AUTOSAR XML (schema 4-3-0)
package /Can_Comm_Diag
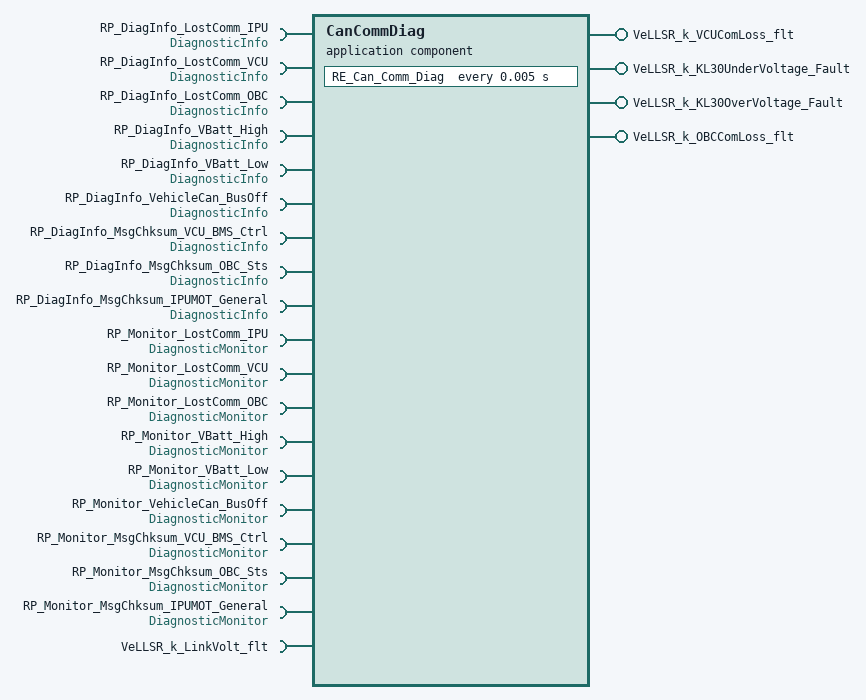
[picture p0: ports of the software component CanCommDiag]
  application sw component type CanCommDiag
    18 x require port:
      RP_DiagInfo_LostComm_IPU: required-interface=DiagnosticInfo
      RP_DiagInfo_LostComm_VCU: required-interface=DiagnosticInfo
      RP_DiagInfo_LostComm_OBC: required-interface=DiagnosticInfo
      RP_DiagInfo_VBatt_High: required-interface=DiagnosticInfo
      RP_DiagInfo_VBatt_Low: required-interface=DiagnosticInfo
      RP_DiagInfo_VehicleCan_BusOff: required-interface=DiagnosticInfo
      RP_DiagInfo_MsgChksum_VCU_BMS_Ctrl: required-interface=DiagnosticInfo
      RP_DiagInfo_MsgChksum_OBC_Sts: required-interface=DiagnosticInfo
      RP_DiagInfo_MsgChksum_IPUMOT_General: required-interface=DiagnosticInfo
      RP_Monitor_LostComm_IPU: required-interface=DiagnosticMonitor
      RP_Monitor_LostComm_VCU: required-interface=DiagnosticMonitor
      RP_Monitor_LostComm_OBC: required-interface=DiagnosticMonitor
      RP_Monitor_VBatt_High: required-interface=DiagnosticMonitor
      RP_Monitor_VBatt_Low: required-interface=DiagnosticMonitor
      RP_Monitor_VehicleCan_BusOff: required-interface=DiagnosticMonitor
      RP_Monitor_MsgChksum_VCU_BMS_Ctrl: required-interface=DiagnosticMonitor
      RP_Monitor_MsgChksum_OBC_Sts: required-interface=DiagnosticMonitor
      RP_Monitor_MsgChksum_IPUMOT_General: required-interface=DiagnosticMonitor
    provide port VeLLSR_k_VCUComLoss_flt: provided-interface=VeLLSR_k_VCUComLoss_flt
    require port VeLLSR_k_LinkVolt_flt: required-interface=VeLLSR_k_LinkVolt_flt
    provide port VeLLSR_k_KL30UnderVoltage_Fault: provided-interface=VeLLSR_k_KL30UnderVoltage_Fault
    provide port VeLLSR_k_KL30OverVoltage_Fault: provided-interface=VeLLSR_k_KL30OverVoltage_Fault
    provide port VeLLSR_k_OBCComLoss_flt: provided-interface=VeLLSR_k_OBCComLoss_flt
    behavior SwcInternalBehavior_0: data-type-mapping=[DHSR_CodeDataTypeMappingsSet, HVSR_CodeDataTypeMappingsSet]
      timing event TimingEvent_0: start-on-event=RE_Can_Comm_Diag, period=0.005
      runnable RE_Can_Comm_Diag: symbol=Perform_Can_Comm_Diagnostics
        data-read-access:
          access DRA_VeLLSR_k_LinkVolt_flt_0: accessed-variable=VeLLSR_k_LinkVolt_flt.VeLLSR_k_LinkVolt_flt
        data-write-access:
          4 x access:
            DWA_VeLLSR_k_VCUComLoss_flt_0: accessed-variable=VeLLSR_k_VCUComLoss_flt.VeLLSR_k_VCUComLoss_flt
            DWA_VeLLSR_k_KL30OverVoltage_Fault_0: accessed-variable=VeLLSR_k_KL30OverVoltage_Fault.VeLLSR_k_KL30OverVoltage_Fault
            DWA_VeLLSR_k_KL30UnderVoltage_Fault_0: accessed-variable=VeLLSR_k_KL30UnderVoltage_Fault.VeLLSR_k_KL30UnderVoltage_Fault
            DWA_VeLLSR_k_OBCComLoss_flt_0: accessed-variable=VeLLSR_k_OBCComLoss_flt.VeLLSR_k_OBCComLoss_flt
        6 x parameter access:
          PAP_KeLLSR_b_VCUComLoss_flt_En: accessed-parameter=KeLLSR_b_VCUComLoss_flt_En
          PAP_KeLLSR_k_VCUComLoss_flt_Val: accessed-parameter=KeLLSR_k_VCUComLoss_flt_Val
          PAP_KeLLSR_b_KL30Undervoltage_Fault_En: accessed-parameter=KeLLSR_b_KL30UnderVoltage_Fault_En
          PAP_KeLLSR_k_KL30UnderVoltage_Fault_Val: accessed-parameter=KeLLSR_k_KL30UnderVoltage_Fault_Val
          PAP_KeLLSR_b_KL30OverVoltage_Fault_En: accessed-parameter=KeLLSR_b_KL30OverVoltage_Fault_En
          PAP_KeLLSR_k_KL30OverVoltage_Fault_Val: accessed-parameter=KeLLSR_k_KL30OverVoltage_Fault_Val
        81 x sync call:
          SynchronousServerCallPoint_01: operation=RP_Monitor_LostComm_IPU.SetEventStatus
          SynchronousServerCallPoint_02: operation=RP_Monitor_LostComm_IPU.ResetEventStatus
          SynchronousServerCallPoint_03: operation=RP_Monitor_LostComm_IPU.PrestoreFreezeFrame
          SynchronousServerCallPoint_04: operation=RP_Monitor_LostComm_IPU.ClearPrestoredFreezeFrame
          SynchronousServerCallPoint_05: operation=RP_DiagInfo_LostComm_OBC.GetEventStatus
          SynchronousServerCallPoint_06: operation=RP_DiagInfo_LostComm_OBC.GetEventFailed
          SynchronousServerCallPoint_07: operation=RP_DiagInfo_LostComm_OBC.GetEventTested
          SynchronousServerCallPoint_08: operation=RP_DiagInfo_LostComm_OBC.GetDTCOfEvent
          SynchronousServerCallPoint_09: operation=RP_DiagInfo_LostComm_OBC.GetFaultDetectionCounter
          SynchronousServerCallPoint_10: operation=RP_Monitor_LostComm_OBC.SetEventStatus
          SynchronousServerCallPoint_11: operation=RP_Monitor_LostComm_OBC.ResetEventStatus
          SynchronousServerCallPoint_12: operation=RP_Monitor_LostComm_OBC.PrestoreFreezeFrame
          SynchronousServerCallPoint_13: operation=RP_Monitor_LostComm_OBC.ClearPrestoredFreezeFrame
          SynchronousServerCallPoint_14: operation=RP_Monitor_LostComm_VCU.SetEventStatus
          SynchronousServerCallPoint_15: operation=RP_Monitor_LostComm_VCU.ResetEventStatus
          SynchronousServerCallPoint_16: operation=RP_Monitor_LostComm_VCU.PrestoreFreezeFrame
          SynchronousServerCallPoint_17: operation=RP_Monitor_LostComm_VCU.ClearPrestoredFreezeFrame
          SynchronousServerCallPoint_18: operation=RP_DiagInfo_LostComm_IPU.GetEventStatus
          SynchronousServerCallPoint_19: operation=RP_DiagInfo_LostComm_IPU.GetEventFailed
          SynchronousServerCallPoint_20: operation=RP_DiagInfo_LostComm_IPU.GetEventTested
          SynchronousServerCallPoint_21: operation=RP_DiagInfo_LostComm_IPU.GetDTCOfEvent
          SynchronousServerCallPoint_22: operation=RP_DiagInfo_LostComm_IPU.GetFaultDetectionCounter
          SynchronousServerCallPoint_23: operation=RP_DiagInfo_LostComm_VCU.GetEventStatus
          SynchronousServerCallPoint_24: operation=RP_DiagInfo_LostComm_VCU.GetEventFailed
          SynchronousServerCallPoint_25: operation=RP_DiagInfo_LostComm_VCU.GetEventTested
          SynchronousServerCallPoint_26: operation=RP_DiagInfo_LostComm_VCU.GetDTCOfEvent
          SynchronousServerCallPoint_27: operation=RP_DiagInfo_LostComm_VCU.GetFaultDetectionCounter
          SSCP_GES_VBatt_High: operation=RP_DiagInfo_VBatt_High.GetEventStatus
          SSCP_GEF_VBatt_High: operation=RP_DiagInfo_VBatt_High.GetEventFailed
          SSCP_GET_VBatt_High: operation=RP_DiagInfo_VBatt_High.GetEventTested
          SSCP_GDTC_VBatt_High: operation=RP_DiagInfo_VBatt_High.GetDTCOfEvent
          SSCP_GFDC_VBatt_High: operation=RP_DiagInfo_VBatt_High.GetFaultDetectionCounter
          SSCP_SES_VBatt_High: operation=RP_Monitor_VBatt_High.SetEventStatus
          SSCP_RES_VBatt_High: operation=RP_Monitor_VBatt_High.ResetEventStatus
          SSCP_PFF_VBatt_High: operation=RP_Monitor_VBatt_High.PrestoreFreezeFrame
          SSCP_CPFF_VBatt_High: operation=RP_Monitor_VBatt_High.ClearPrestoredFreezeFrame
          SSCP_GES_VBatt_Low: operation=RP_DiagInfo_VBatt_Low.GetEventStatus
          SSCP_GEF_VBatt_Low: operation=RP_DiagInfo_VBatt_Low.GetEventFailed
          SSCP_GET_VBatt_Low: operation=RP_DiagInfo_VBatt_Low.GetEventTested
          SSCP_GDTC_VBatt_Low: operation=RP_DiagInfo_VBatt_Low.GetDTCOfEvent
          SSCP_GFDC_VBatt_Low: operation=RP_DiagInfo_VBatt_Low.GetFaultDetectionCounter
          SSCP_SES_VBatt_Low: operation=RP_Monitor_VBatt_Low.SetEventStatus
          SSCP_RES_VBatt_Low: operation=RP_Monitor_VBatt_Low.ResetEventStatus
          SSCP_PFF_VBatt_Low: operation=RP_Monitor_VBatt_Low.PrestoreFreezeFrame
          SSCP_CPFF_VBatt_Low: operation=RP_Monitor_VBatt_Low.ClearPrestoredFreezeFrame
          SSCP_GES_VehicleCan_BusOff: operation=RP_DiagInfo_VehicleCan_BusOff.GetEventStatus
          SSCP_GEF_VehicleCan_BusOff: operation=RP_DiagInfo_VehicleCan_BusOff.GetEventFailed
          SSCP_GET_VehicleCan_BusOff: operation=RP_DiagInfo_VehicleCan_BusOff.GetEventTested
          SSCP_GDTC_VehicleCan_BusOff: operation=RP_DiagInfo_VehicleCan_BusOff.GetDTCOfEvent
          SSCP_GFDC_VehicleCan_BusOff: operation=RP_DiagInfo_VehicleCan_BusOff.GetFaultDetectionCounter
          SSCP_SES_VehicleCan_BusOff: operation=RP_Monitor_VehicleCan_BusOff.SetEventStatus
          SSCP_RES_VehicleCan_BusOff: operation=RP_Monitor_VehicleCan_BusOff.ResetEventStatus
          SSCP_PFF_VehicleCan_BusOff: operation=RP_Monitor_VehicleCan_BusOff.PrestoreFreezeFrame
          SSCP_CPFF_VehicleCan_BusOff: operation=RP_Monitor_VehicleCan_BusOff.ClearPrestoredFreezeFrame
          SSCP_GES_MsgChksum_VCU_BMS_Ctrl: operation=RP_DiagInfo_MsgChksum_VCU_BMS_Ctrl.GetEventStatus
          SSCP_GEF_MsgChksum_VCU_BMS_Ctrl: operation=RP_DiagInfo_MsgChksum_VCU_BMS_Ctrl.GetEventFailed
          SSCP_GET_MsgChksum_VCU_BMS_Ctrl: operation=RP_DiagInfo_MsgChksum_VCU_BMS_Ctrl.GetEventTested
          SSCP_GDTC_MsgChksum_VCU_BMS_Ctrl: operation=RP_DiagInfo_MsgChksum_VCU_BMS_Ctrl.GetDTCOfEvent
          SSCP_GFDC_MsgChksum_VCU_BMS_Ctrl: operation=RP_DiagInfo_MsgChksum_VCU_BMS_Ctrl.GetFaultDetectionCounter
          SSCP_SES_MsgChksum_VCU_BMS_Ctrl: operation=RP_Monitor_MsgChksum_VCU_BMS_Ctrl.SetEventStatus
          SSCP_RES_MsgChksum_VCU_BMS_Ctrl: operation=RP_Monitor_MsgChksum_VCU_BMS_Ctrl.ResetEventStatus
          SSCP_PFF_MsgChksum_VCU_BMS_Ctrl: operation=RP_Monitor_MsgChksum_VCU_BMS_Ctrl.PrestoreFreezeFrame
          SSCP_CPFF_MsgChksum_VCU_BMS_Ctrl: operation=RP_Monitor_MsgChksum_VCU_BMS_Ctrl.ClearPrestoredFreezeFrame
          SSCP_GES_MsgChksum_OBC_Sts: operation=RP_DiagInfo_MsgChksum_OBC_Sts.GetEventStatus
          SSCP_GEF_MsgChksum_OBC_Sts: operation=RP_DiagInfo_MsgChksum_OBC_Sts.GetEventFailed
          SSCP_GET_MsgChksum_OBC_Sts: operation=RP_DiagInfo_MsgChksum_OBC_Sts.GetEventTested
          SSCP_GDTC_MsgChksum_OBC_Sts: operation=RP_DiagInfo_MsgChksum_OBC_Sts.GetDTCOfEvent
          SSCP_GFDC_MsgChksum_OBC_Sts: operation=RP_DiagInfo_MsgChksum_OBC_Sts.GetFaultDetectionCounter
          SSCP_SES_MsgChksum_OBC_Sts: operation=RP_Monitor_MsgChksum_OBC_Sts.SetEventStatus
          SSCP_RES_MsgChksum_OBC_Sts: operation=RP_Monitor_MsgChksum_OBC_Sts.ResetEventStatus
          SSCP_PFF_MsgChksum_OBC_Sts: operation=RP_Monitor_MsgChksum_OBC_Sts.PrestoreFreezeFrame
          SSCP_CPFF_MsgChksum_OBC_Sts: operation=RP_Monitor_MsgChksum_OBC_Sts.ClearPrestoredFreezeFrame
          SSCP_GES_MsgChksum_IPUMOT_General: operation=RP_DiagInfo_MsgChksum_IPUMOT_General.GetEventStatus
          SSCP_GEF_MsgChksum_IPUMOT_General: operation=RP_DiagInfo_MsgChksum_IPUMOT_General.GetEventFailed
          SSCP_GET_MsgChksum_IPUMOT_General: operation=RP_DiagInfo_MsgChksum_IPUMOT_General.GetEventTested
          SSCP_GDTC_MsgChksum_IPUMOT_General: operation=RP_DiagInfo_MsgChksum_IPUMOT_General.GetDTCOfEvent
          SSCP_GFDC_MsgChksum_IPUMOT_General: operation=RP_DiagInfo_MsgChksum_IPUMOT_General.GetFaultDetectionCounter
          SSCP_SES_MsgChksum_IPUMOT_General: operation=RP_Monitor_MsgChksum_IPUMOT_General.SetEventStatus
          SSCP_RES_MsgChksum_IPUMOT_General: operation=RP_Monitor_MsgChksum_IPUMOT_General.ResetEventStatus
          SSCP_PFF_MsgChksum_IPUMOT_General: operation=RP_Monitor_MsgChksum_IPUMOT_General.PrestoreFreezeFrame
          SSCP_CPFF_MsgChksum_IPUMOT_General: operation=RP_Monitor_MsgChksum_IPUMOT_General.ClearPrestoredFreezeFrame
      shared-parameters:
        6 x parameter data prototype, all with sw-calibration-access=READ-WRITE, init-value=0:
          KeLLSR_b_VCUComLoss_flt_En: implementation-data-type=boolean, type=boolean
          KeLLSR_k_VCUComLoss_flt_Val: implementation-data-type=UInt8, type=UInt8
          KeLLSR_b_KL30UnderVoltage_Fault_En: implementation-data-type=Boolean, type=Boolean
          KeLLSR_k_KL30UnderVoltage_Fault_Val: implementation-data-type=UInt8, type=uint8
          KeLLSR_b_KL30OverVoltage_Fault_En: implementation-data-type=Boolean, type=Boolean
          KeLLSR_k_KL30OverVoltage_Fault_Val: implementation-data-type=UInt8, type=UInt8
  4 x sender receiver interface:
    VeLLSR_b_VCUComLossFaulted_0
      data VeLLSR_b_VCUComLossFaulted_0: type=boolean
    VeLLSR_k_LinkVolt_flt
      data VeLLSR_k_LinkVolt_flt: type=uint8
    VeLLSR_k_KL30UnderVoltage_Fault
      data VeLLSR_k_KL30UnderVoltage_Fault: type=uint8
    VeLLSR_k_KL30OverVoltage_Fault
      data VeLLSR_k_KL30OverVoltage_Fault: type=uint8
  data type mapping set Can_Comm_Diag_MappingsSet
